# ESP32-P4 register map
Vendor: ESPRESSIF SYSTEMS (SHANGHAI) CO., LTD.; Series: ESP32 P-Series; File version: 3
CPU: RV32IMAFC r0p0, little endian, no MPU, FPU, 0 interrupt priority bits
Address unit: 32 bits
Registers are 32-bit, read-write, reset 0x0 unless marked. A register's access mark holds for its fields unless they carry their own. Offsets are from the block's base; [hi:lo] are bit positions; lines under a group give offsets from that group; {n}, {i} and the like mark numbered series.

## TIMG0 — Timer Group 0
Base 0x500C2000
Same registers: TIMG1 0x500C3000
{0x0+0x24*i} T{i} (i=0..1) group — Cluster T{i}, containing T?CONFIG, T?LO, T?HI, T?UPDATE, T?ALARMLO, T?ALARMHI, T?LOADLO, T?LOADHI, T?LOAD
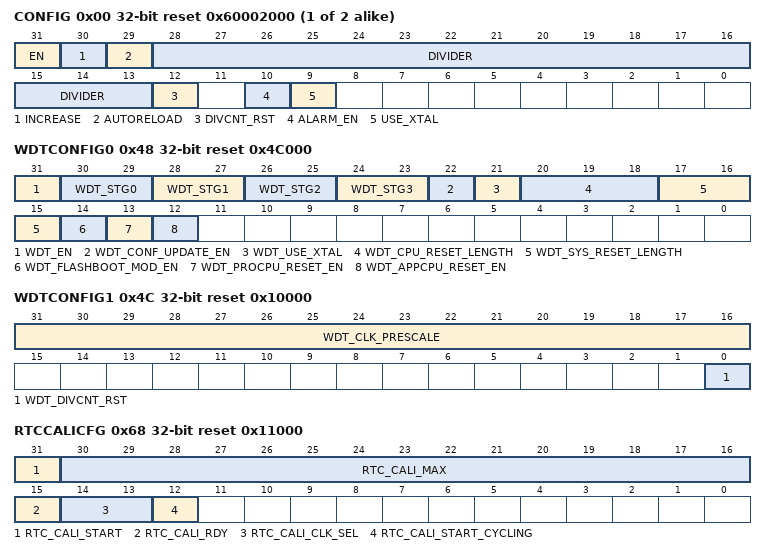
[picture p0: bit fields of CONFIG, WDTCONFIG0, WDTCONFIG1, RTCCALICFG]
  0x00 CONFIG access per field reset 0x60002000 — Timer 0 configuration register
    [31] EN rw — When set, the timer %s time-base counter is enabled.
    [30] INCREASE rw — When set, the timer %s time-base counter will increment every clock tick. When cleared, the timer %s time-base counter will decrement.
    [29] AUTORELOAD rw — When set, timer %s auto-reload at alarm is enabled.
    [28:13] DIVIDER rw — Timer %s clock (T%s_clk) prescaler value.
    [12] DIVCNT_RST wo — When set, Timer %s 's clock divider counter will be reset.
    [10] ALARM_EN rw — When set, the alarm is enabled. This bit is automatically cleared once an alarm occurs.
    [9] USE_XTAL rw — 1: Use XTAL_CLK as the source clock of timer group. 0: Use APB_CLK as the source clock of timer group.
  0x04 LO ro — Timer 0 current value, low 32 bits
    [31:0] LO — After writing to TIMG_T%sUPDATE_REG, the low 32 bits of the time-base counter of timer %s can be read here.
  0x08 HI ro — Timer 0 current value, high 22 bits
    [21:0] HI — After writing to TIMG_T%sUPDATE_REG, the high 22 bits of the time-base counter of timer %s can be read here.
  0x0C UPDATE — Write to copy current timer value to TIMGn_T0_(LO/HI)_REG
    [31] UPDATE — After writing 0 or 1 to TIMG_T%sUPDATE_REG, the counter value is latched.
  0x10 ALARMLO — Timer 0 alarm value, low 32 bits
    [31:0] ALARM_LO — Timer %s alarm trigger time-base counter value, low 32 bits.
  0x14 ALARMHI — Timer 0 alarm value, high bits
    [21:0] ALARM_HI — Timer %s alarm trigger time-base counter value, high 22 bits.
  0x18 LOADLO — Timer 0 reload value, low 32 bits
    [31:0] LOAD_LO — Low 32 bits of the value that a reload will load onto timer %s time-base Counter.
  0x1C LOADHI — Timer 0 reload value, high 22 bits
    [21:0] LOAD_HI — High 22 bits of the value that a reload will load onto timer %s time-base counter.
  0x20 LOAD wo — Write to reload timer from TIMG_T0_(LOADLOLOADHI)_REG
    [31:0] LOAD — Write any value to trigger a timer %s time-base counter reload.
0x48 WDTCONFIG0 access per field reset 0x4C000 — Watchdog timer configuration register
  [31] WDT_EN rw — When set, MWDT is enabled.
  [30-2n:29-2n] WDT_STG{n} rw (n=0..3) — Stage {n} configuration. 0: off, 1: interrupt, 2: reset CPU, 3: reset system.
  [22] WDT_CONF_UPDATE_EN wo — update the WDT configuration registers
  [21] WDT_USE_XTAL rw — choose WDT clock:0-apb_clk, 1-xtal_clk.
  [20:18] WDT_CPU_RESET_LENGTH rw — CPU reset signal length selection. 0: 100 ns, 1: 200 ns, 2: 300 ns, 3: 400 ns, 4: 500 ns, 5: 800 ns, 6: 1.6 us, 7: 3.2 us.
  [17:15] WDT_SYS_RESET_LENGTH rw — System reset signal length selection. 0: 100 ns, 1: 200 ns, 2: 300 ns, 3: 400 ns, 4: 500 ns, 5: 800 ns, 6: 1.6 us, 7: 3.2 us.
  [14] WDT_FLASHBOOT_MOD_EN rw — When set, Flash boot protection is enabled.
  [13] WDT_PROCPU_RESET_EN rw — WDT reset CPU enable.
  [12] WDT_APPCPU_RESET_EN rw — WDT reset CPU enable.
0x4C WDTCONFIG1 access per field reset 0x10000 — Watchdog timer prescaler register
  [31:16] WDT_CLK_PRESCALE rw — MWDT clock prescaler value. MWDT clock period = 12.5 ns * TIMG_WDT_CLK_PRESCALE.
  [0] WDT_DIVCNT_RST wo — When set, WDT 's clock divider counter will be reset.
{0x48+4i} WDTCONFIG{i} (i=2..5) reset 0x18CBA80 — Watchdog timer stage timeout value
  [31:0] HOLD — Stage 0 timeout value, in MWDT clock cycles.
0x60 WDTFEED wo — Write to feed the watchdog timer
  [31:0] WDT_FEED — Write any value to feed the MWDT. (WO)
0x64 WDTWPROTECT reset 0x50D83AA1 — Watchdog write protect register
  [31:0] WDT_WKEY — If the register contains a different value than its reset value, write protection is enabled.
0x68 RTCCALICFG access per field reset 0x11000 — RTC calibration configure register
  [31] RTC_CALI_START rw — Set this bit to start one-shot frequency calculation.
  [30:16] RTC_CALI_MAX rw — Configure the time to calculate RTC slow clock's frequency.
  [15] RTC_CALI_RDY ro — indicate one-shot frequency calculation is done.
  [14:13] RTC_CALI_CLK_SEL rw — 0:rtc slow clock. 1:clk_8m, 2:xtal_32k.
  [12] RTC_CALI_START_CYCLING rw — 0: one-shot frequency calculation,1: periodic frequency calculation,
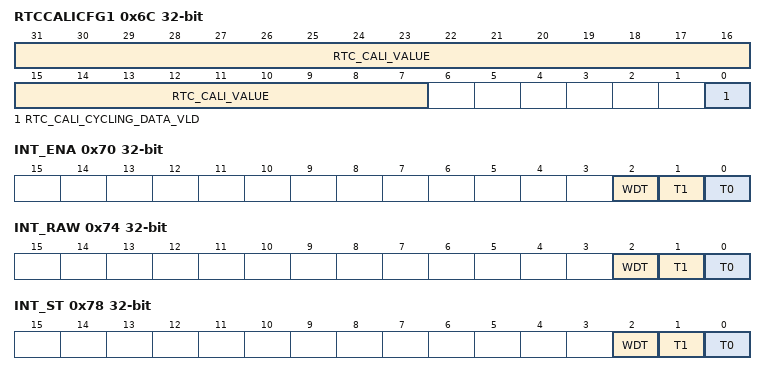
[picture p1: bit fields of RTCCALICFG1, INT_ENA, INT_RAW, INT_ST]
0x6C RTCCALICFG1 ro — RTC calibration configure1 register
  [31:7] RTC_CALI_VALUE — When one-shot or periodic frequency calculation is done, read this value to calculate RTC slow clock's frequency.
  [0] RTC_CALI_CYCLING_DATA_VLD — indicate periodic frequency calculation is done.
0x70 INT_ENA — Interrupt enable bits
  [2] WDT — The interrupt enable bit for the TIMG_WDT_INT interrupt.
  [n] T{n} (n=0..1) — The interrupt enable bit for the TIMG_T{n}_INT interrupt.
0x74 INT_RAW ro — Raw interrupt status
  [2] WDT — The raw interrupt status bit for the TIMG_WDT_INT interrupt.
  [n] T{n} (n=0..1) — The raw interrupt status bit for the TIMG_T{n}_INT interrupt.
0x78 INT_ST ro — Masked interrupt status
  [2] WDT — The masked interrupt status bit for the TIMG_WDT_INT interrupt.
  [n] T{n} (n=0..1) — The masked interrupt status bit for the TIMG_T{n}_INT interrupt.
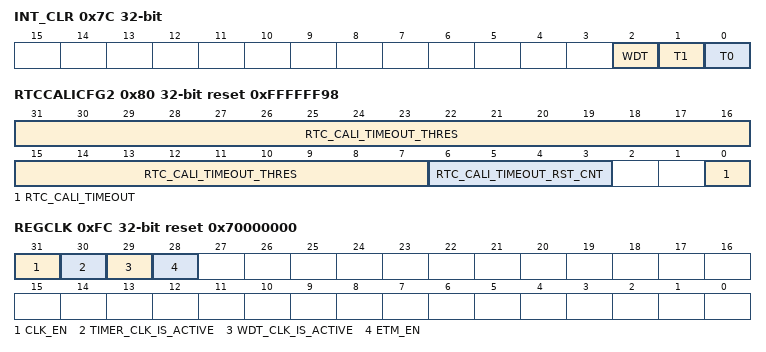
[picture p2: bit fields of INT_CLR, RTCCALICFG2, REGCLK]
0x7C INT_CLR wo — Interrupt clear bits
  [2] WDT write-1-clears — Set this bit to clear the TIMG_WDT_INT interrupt.
  [n] T{n} (n=0..1) write-1-clears — Set this bit to clear the TIMG_T{n}_INT interrupt.
0x80 RTCCALICFG2 access per field reset 0xFFFFFF98 — Timer group calibration register
  [31:7] RTC_CALI_TIMEOUT_THRES rw — Threshold value for the RTC calibration timer. If the calibration timer's value exceeds this threshold, a timeout is triggered.
  [6:3] RTC_CALI_TIMEOUT_RST_CNT rw — Cycles that release calibration timeout reset
  [0] RTC_CALI_TIMEOUT ro — RTC calibration timeout indicator
0xF8 NTIMERS_DATE reset 0x2209142 — Timer version control register
  [27:0] NTIMGS_DATE
0xFC REGCLK reset 0x70000000 — Timer group clock gate register
  [31] CLK_EN — Register clock gate signal. 1: Registers can be read and written to by software. 0: Registers can not be read or written to by software.
  [30] TIMER_CLK_IS_ACTIVE — enable Timer 30's clock
  [29] WDT_CLK_IS_ACTIVE — enable WDT's clock
  [28] ETM_EN — enable timer's etm task and event
